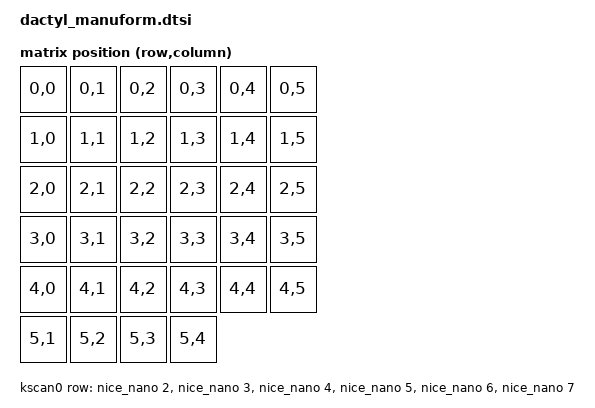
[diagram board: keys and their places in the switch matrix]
// This file was generated from a template. Edit it to match your keyboard.
// See https://zmk.dev/docs/development/hardware-integration/new-shield for more
// instructions.

//#include "dactyl_manuform-layouts.dtsi"

#include <dt-bindings/zmk/matrix_transform.h>

/ {
    kscan0: kscan0 {
        compatible = "zmk,kscan-gpio-matrix";
        diode-direction = "col2row";
        wakeup-source;

        row-gpios = <
            &nice_nano 2  (GPIO_ACTIVE_HIGH | GPIO_PULL_DOWN)
            &nice_nano 3  (GPIO_ACTIVE_HIGH | GPIO_PULL_DOWN)
            &nice_nano 4  (GPIO_ACTIVE_HIGH | GPIO_PULL_DOWN)
            &nice_nano 5  (GPIO_ACTIVE_HIGH | GPIO_PULL_DOWN)
            &nice_nano 6  (GPIO_ACTIVE_HIGH | GPIO_PULL_DOWN)
            &nice_nano 7  (GPIO_ACTIVE_HIGH | GPIO_PULL_DOWN)
        >;
    };

    default_transform: keymap_transform0 {
        compatible = "zmk,matrix-transform";
        rows = <6>;
        columns = <12>;

        map = <
            RC(0,0)  RC(0,1)  RC(0,2)  RC(0,3)  RC(0,4)  RC(0,5)
            RC(1,0)  RC(1,1)  RC(1,2)  RC(1,3)  RC(1,4)  RC(1,5)
            RC(2,0)  RC(2,1)  RC(2,2)  RC(2,3)  RC(2,4)  RC(2,5)
            RC(3,0)  RC(3,1)  RC(3,2)  RC(3,3)  RC(3,4)  RC(3,5)
            RC(4,0)  RC(4,1)  RC(4,2)  RC(4,3)  RC(4,4)  RC(4,5)

            RC(5,1)  RC(5,2)  RC(5,3)  RC(5,4)
        >;
    };

    chosen {
        zmk,kscan = &kscan0;
        zmk,physical-layout = &default_transform;
    };
};

